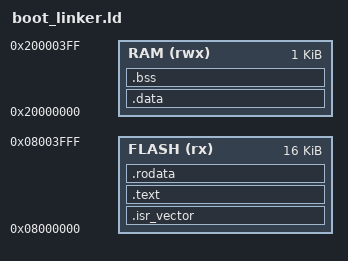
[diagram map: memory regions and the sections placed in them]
MEMORY {
    FLASH (rx) : ORIGIN = 0x08000000, LENGTH = 16K
    RAM (rwx)  : ORIGIN = 0x20000000, LENGTH = 1K
}

SECTIONS {
    .isr_vector : {
        . = ALIGN(4);
        KEEP(*(.isr_vector))
        . = ALIGN(4);
    } >FLASH

    .text : {
        . = ALIGN(4);
        *(.text)
        *(.text*)
        . = ALIGN(4);
    } >FLASH

    .rodata : {
        . = ALIGN(4);
        *(.rodata)
        *(.rodata*)
        . = ALIGN(4);
    } >FLASH

    _sidata = .;  /* .data 段在 FLASH 中的起始地址 */

    .data : AT(_sidata) {
        . = ALIGN(4);
        _sdata = .;
        *(.data)
        *(.data*)
        . = ALIGN(4);
        _edata = .;
    } >RAM

    .bss : {
        . = ALIGN(4);
        _sbss = .;
        *(.bss)
        *(.bss*)
        . = ALIGN(4);
        _ebss = .;
    } >RAM

    _estack = ORIGIN(RAM) + LENGTH(RAM);
}
